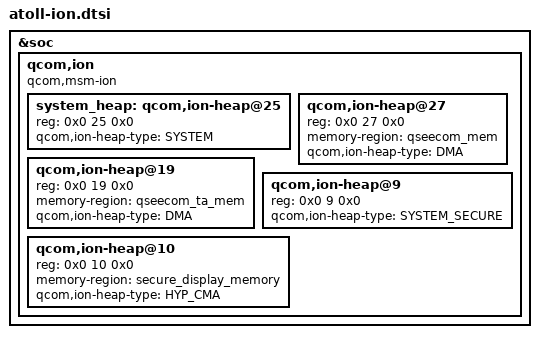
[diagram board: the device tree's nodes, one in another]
/* Copyright (c) 2019, The Linux Foundation. All rights reserved.
 *
 * This program is free software; you can redistribute it and/or modify
 * it under the terms of the GNU General Public License version 2 and
 * only version 2 as published by the Free Software Foundation.
 *
 * This program is distributed in the hope that it will be useful,
 * but WITHOUT ANY WARRANTY; without even the implied warranty of
 * MERCHANTABILITY or FITNESS FOR A PARTICULAR PURPOSE.  See the
 * GNU General Public License for more details.
 */

&soc {
	qcom,ion {
		compatible = "qcom,msm-ion";
		#address-cells = <1>;
		#size-cells = <0>;

		system_heap: qcom,ion-heap@25 {
			reg = <0x0 25 0x0>;
			qcom,ion-heap-type = "SYSTEM";
		};

		qcom,ion-heap@27 { /* QSEECOM HEAP */
			reg = <0x0 27 0x0>;
			memory-region = <&qseecom_mem>;
			qcom,ion-heap-type = "DMA";
		};

		qcom,ion-heap@19 { /* QSEECOM TA HEAP */
			reg = <0x0 19 0x0>;
			memory-region = <&qseecom_ta_mem>;
			qcom,ion-heap-type = "DMA";
		};

		qcom,ion-heap@9 {
			reg = <0x0 9 0x0>;
			qcom,ion-heap-type = "SYSTEM_SECURE";
		};

		qcom,ion-heap@10 { /* SECURE DISPLAY HEAP */
			reg = <0x0 10 0x0>;
			memory-region = <&secure_display_memory>;
			qcom,ion-heap-type = "HYP_CMA";
		};
	};
};
